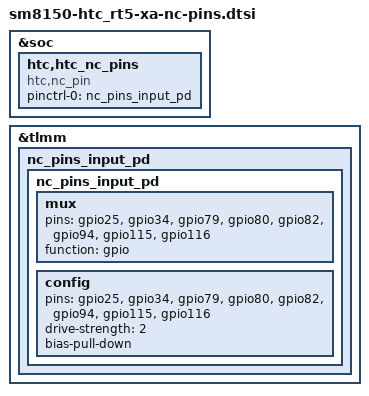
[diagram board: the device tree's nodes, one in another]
/* Copyright (c) 2016, The Linux Foundation. All rights reserved.
 *
 * This program is free software; you can redistribute it and/or modify
 * it under the terms of the GNU General Public License version 2 and
 * only version 2 as published by the Free Software Foundation.
 *
 * This program is distributed in the hope that it will be useful,
 * but WITHOUT ANY WARRANTY; without even the implied warranty of
 * MERCHANTABILITY or FITNESS FOR A PARTICULAR PURPOSE.  See the
 * GNU General Public License for more details.
 */

&soc {
	htc,htc_nc_pins {
		compatible = "htc,nc_pin";

		pinctrl-names = "default";
		pinctrl-0 = <&nc_pins_input_pd>;
	};
};

&tlmm {
	nc_pins_input_pd {
		nc_pins_input_pd: nc_pins_input_pd {
			mux {
				pins =	"gpio25",
						"gpio34",
						"gpio79",
						"gpio80",
						"gpio82",
						"gpio94",
						"gpio115",
						"gpio116";

				function = "gpio";
			};

			config {
				pins =	"gpio25",
						"gpio34",
						"gpio79",
						"gpio80",
						"gpio82",
						"gpio94",
						"gpio115",
						"gpio116";

				drive-strength = <2>;  /* 2 mA */
				bias-pull-down;        /* PULL DOWN */
			};
		};
	};

};
